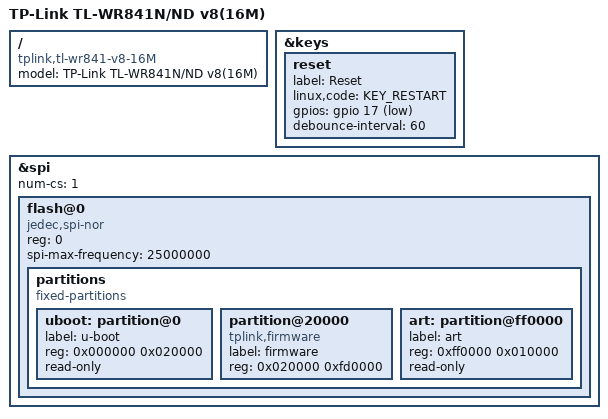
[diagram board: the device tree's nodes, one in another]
// SPDX-License-Identifier: GPL-2.0-or-later OR MIT
/dts-v1/;

#include "ar9341_tplink.dtsi"

/ {
	model = "TP-Link TL-WR841N/ND v8(16M)";
	compatible = "tplink,tl-wr841-v8-16M", "qca,ar9341";
};

&keys {
	reset {
		label = "Reset";
		linux,code = <KEY_RESTART>;
		gpios = <&gpio 17 GPIO_ACTIVE_LOW>;
		debounce-interval = <60>;
	};
};

&spi {
	num-cs = <1>;

	status = "okay";

	flash@0 {
		compatible = "jedec,spi-nor";
		reg = <0>;
		spi-max-frequency = <25000000>;

		partitions {
			compatible = "fixed-partitions";
			#address-cells = <1>;
			#size-cells = <1>;

			uboot: partition@0 {
				label = "u-boot";
				reg = <0x000000 0x020000>;
				read-only;
			};

			partition@20000 {
				compatible = "tplink,firmware";
				label = "firmware";
				reg = <0x020000 0xfd0000>;
			};

			art: partition@ff0000 {
				label = "art";
				reg = <0xff0000 0x010000>;
				read-only;
			};
		};
	};
};
